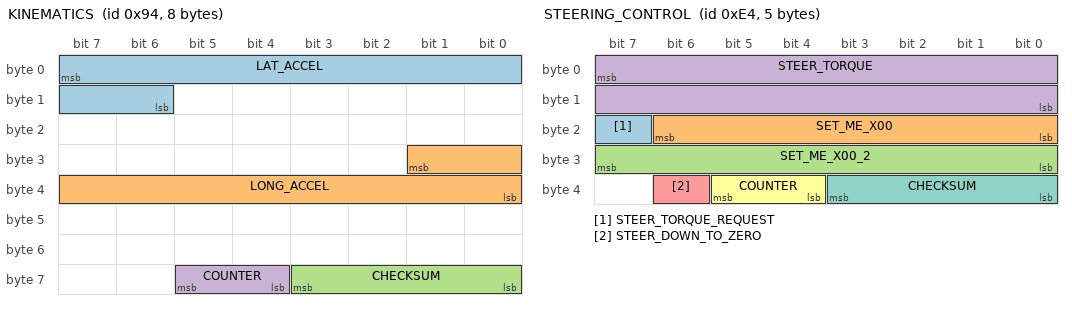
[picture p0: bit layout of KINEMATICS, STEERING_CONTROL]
BO_ 148 KINEMATICS: 8 XXX
 SG_ LAT_ACCEL : 7|10@0+ (-0.035,17.92) [-20|20] "m/s2" EON
 SG_ LONG_ACCEL : 25|10@0+ (-0.035,17.92) [-20|20] "m/s2" EON
 SG_ CHECKSUM : 59|4@0+ (1,0) [0|3] "" EON
 SG_ COUNTER : 61|2@0+ (1,0) [0|3] "" EON

BO_ 228 STEERING_CONTROL: 5 EON
 SG_ STEER_TORQUE_REQUEST : 23|1@0+ (1,0) [0|1] "" EPS
 SG_ SET_ME_X00 : 22|7@0+ (1,0) [0|127] "" EPS
 SG_ SET_ME_X00_2 : 31|8@0+ (1,0) [0|0] "" EPS
 SG_ STEER_TORQUE : 7|16@0- (1,0) [-4096|4096] "" EPS
 SG_ STEER_DOWN_TO_ZERO : 38|1@0+ (1,0) [0|1] "" EPS
 SG_ COUNTER : 37|2@0+ (1,0) [0|3] "" EPS
 SG_ CHECKSUM : 35|4@0+ (1,0) [0|15] "" EPS

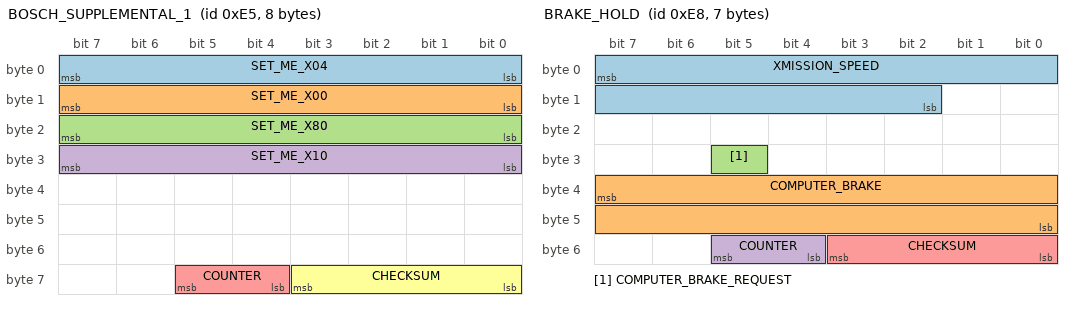
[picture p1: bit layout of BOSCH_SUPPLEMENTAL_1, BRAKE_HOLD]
BO_ 229 BOSCH_SUPPLEMENTAL_1: 8 XXX
 SG_ SET_ME_X04 : 0|8@1+ (1,0) [0|255] "" XXX
 SG_ SET_ME_X00 : 8|8@1+ (1,0) [0|255] "" XXX
 SG_ SET_ME_X80 : 16|8@1+ (1,0) [0|255] "" XXX
 SG_ SET_ME_X10 : 24|8@1+ (1,0) [0|255] "" XXX
 SG_ COUNTER : 61|2@0+ (1,0) [0|3] "" XXX
 SG_ CHECKSUM : 59|4@0+ (1,0) [0|15] "" XXX

BO_ 232 BRAKE_HOLD: 7 XXX
 SG_ XMISSION_SPEED : 7|14@0- (1,0) [1|0] "" XXX
 SG_ COMPUTER_BRAKE : 39|16@0+ (1,0) [0|0] "" XXX
 SG_ COMPUTER_BRAKE_REQUEST : 29|1@0+ (1,0) [0|0] "" XXX
 SG_ COUNTER : 53|2@0+ (1,0) [0|3] "" XXX
 SG_ CHECKSUM : 51|4@0+ (1,0) [0|15] "" XXX

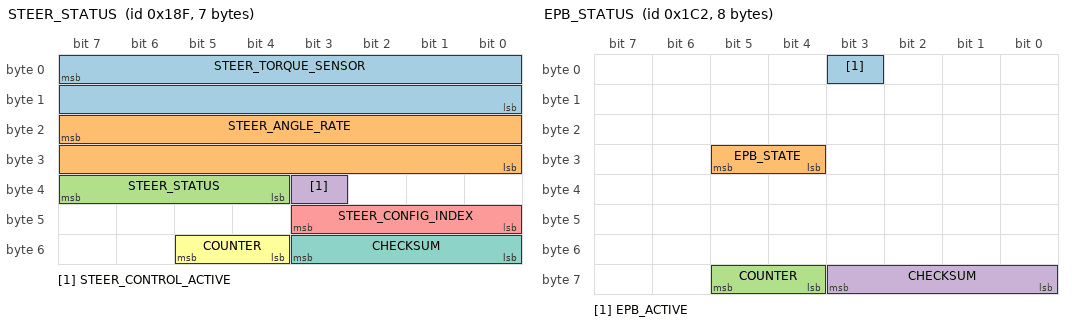
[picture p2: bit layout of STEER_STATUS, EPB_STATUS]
BO_ 399 STEER_STATUS: 7 EPS
 SG_ STEER_TORQUE_SENSOR : 7|16@0- (-1,0) [-31000|31000] "tbd" EON
 SG_ STEER_ANGLE_RATE : 23|16@0- (-0.1,0) [-31000|31000] "deg/s" EON
 SG_ STEER_STATUS : 39|4@0+ (1,0) [0|15] "" EON
 SG_ STEER_CONTROL_ACTIVE : 35|1@0+ (1,0) [0|1] "" EON
 SG_ STEER_CONFIG_INDEX : 43|4@0+ (1,0) [0|15] "" EON
 SG_ COUNTER : 53|2@0+ (1,0) [0|3] "" EON
 SG_ CHECKSUM : 51|4@0+ (1,0) [0|15] "" EON

BO_ 450 EPB_STATUS: 8 EPB
 SG_ EPB_ACTIVE : 3|1@0+ (1,0) [0|1] "" EON
 SG_ EPB_STATE : 29|2@0+ (1,0) [0|3] "" EON
 SG_ COUNTER : 61|2@0+ (1,0) [0|3] "" XXX
 SG_ CHECKSUM : 59|4@0+ (1,0) [0|15] "" XXX

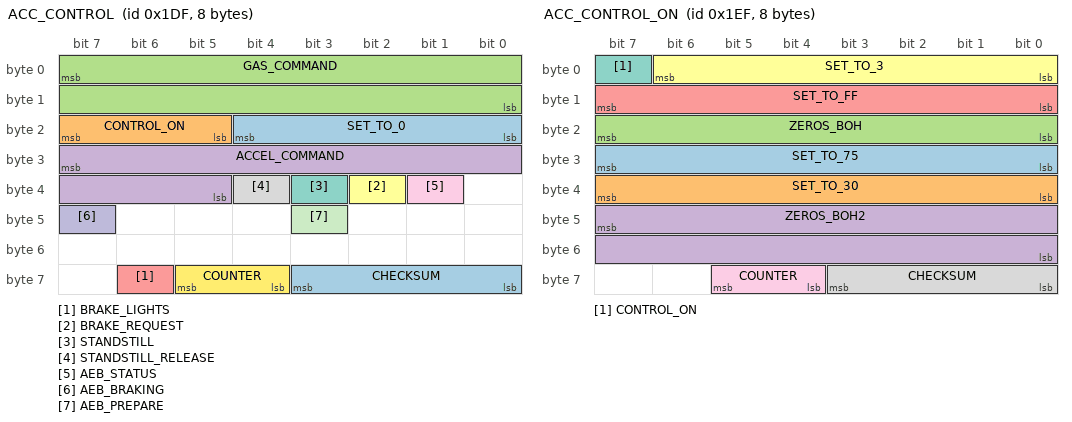
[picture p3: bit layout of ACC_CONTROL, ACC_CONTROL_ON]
BO_ 479 ACC_CONTROL: 8 EON
 SG_ SET_TO_0 : 20|5@0+ (1,0) [0|1] "" XXX
 SG_ CONTROL_ON : 23|3@0+ (1,0) [0|5] "" XXX
 SG_ GAS_COMMAND : 7|16@0- (1,0) [0|0] "" XXX
 SG_ ACCEL_COMMAND : 31|11@0- (0.01,0) [0|0] "m/s2" XXX
 SG_ BRAKE_LIGHTS : 62|1@0+ (1,0) [0|1] "" XXX
 SG_ BRAKE_REQUEST : 34|1@0+ (1,0) [0|1] "" XXX
 SG_ STANDSTILL : 35|1@0+ (1,0) [0|1] "" XXX
 SG_ STANDSTILL_RELEASE : 36|1@0+ (1,0) [0|1] "" XXX
 SG_ AEB_STATUS : 33|1@0+ (1,0) [0|1] "" XXX
 SG_ AEB_BRAKING : 47|1@0+ (1,0) [0|1] "" XXX
 SG_ AEB_PREPARE : 43|1@0+ (1,0) [0|1] "" XXX
 SG_ COUNTER : 61|2@0+ (1,0) [0|3] "" XXX
 SG_ CHECKSUM : 59|4@0+ (1,0) [0|15] "" XXX

BO_ 495 ACC_CONTROL_ON: 8 XXX
 SG_ SET_TO_75 : 31|8@0+ (1,0) [0|255] "" XXX
 SG_ SET_TO_30 : 39|8@0+ (1,0) [0|255] "" XXX
 SG_ ZEROS_BOH : 23|8@0+ (1,0) [0|255] "" XXX
 SG_ ZEROS_BOH2 : 47|16@0+ (1,0) [0|255] "" XXX
 SG_ SET_TO_FF : 15|8@0+ (1,0) [0|255] "" XXX
 SG_ SET_TO_3 : 6|7@0+ (1,0) [0|4095] "" XXX
 SG_ CONTROL_ON : 7|1@0+ (1,0) [0|1] "" XXX
 SG_ CHECKSUM : 59|4@0+ (1,0) [0|15] "" XXX
 SG_ COUNTER : 61|2@0+ (1,0) [0|3] "" XXX

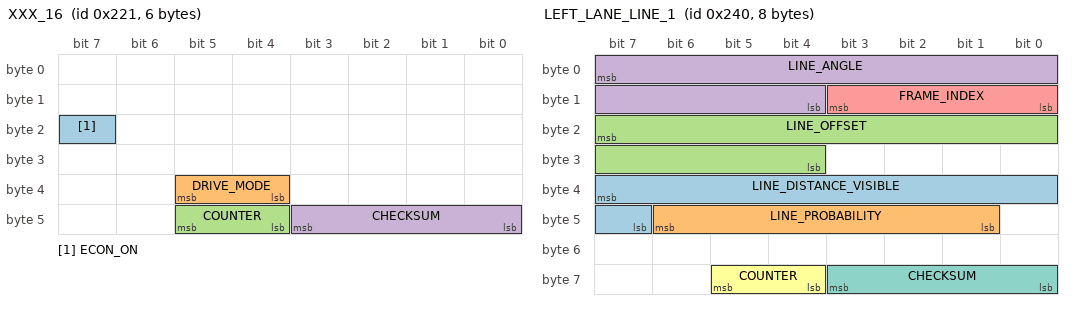
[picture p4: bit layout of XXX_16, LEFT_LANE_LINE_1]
BO_ 545 XXX_16: 6 SCM
 SG_ ECON_ON : 23|1@0+ (1,0) [0|1] "" XXX
 SG_ DRIVE_MODE : 37|2@0+ (1,0) [0|3] "" XXX
 SG_ COUNTER : 45|2@0+ (1,0) [0|3] "" BDY
 SG_ CHECKSUM : 43|4@0+ (1,0) [0|15] "" BDY

BO_ 576 LEFT_LANE_LINE_1: 8 CAM
 SG_ LINE_DISTANCE_VISIBLE : 39|9@0+ (1,0) [0|1] "" XXX
 SG_ LINE_PROBABILITY : 46|6@0+ (0.015625,0) [0|1] "" XXX
 SG_ LINE_OFFSET : 23|12@0+ (0.004,-8.192) [0|1] "Meters" XXX
 SG_ LINE_ANGLE : 7|12@0+ (0.0005,-1.024) [0|1] "" XXX
 SG_ FRAME_INDEX : 8|4@1+ (1,0) [0|15] "" XXX
 SG_ COUNTER : 61|2@0+ (1,0) [0|1] "" XXX
 SG_ CHECKSUM : 59|4@0+ (1,0) [0|1] "" XXX

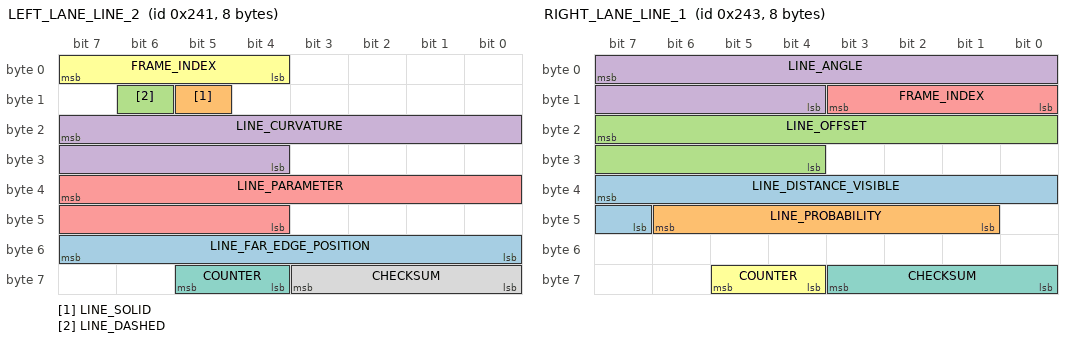
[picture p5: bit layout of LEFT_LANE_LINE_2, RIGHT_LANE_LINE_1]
BO_ 577 LEFT_LANE_LINE_2: 8 CAM
 SG_ LINE_FAR_EDGE_POSITION : 55|8@0+ (1,-128) [0|1] "" XXX
 SG_ LINE_SOLID : 13|1@0+ (1,0) [0|1] "" XXX
 SG_ LINE_DASHED : 14|1@0+ (1,0) [0|1] "" XXX
 SG_ LINE_CURVATURE : 23|12@0+ (0.00001,-0.02048) [0|1] "" XXX
 SG_ LINE_PARAMETER : 39|12@0+ (1,0) [0|1] "" XXX
 SG_ FRAME_INDEX : 7|4@0+ (1,0) [0|15] "" XXX
 SG_ COUNTER : 61|2@0+ (1,0) [0|1] "" XXX
 SG_ CHECKSUM : 59|4@0+ (1,0) [0|1] "" XXX

BO_ 579 RIGHT_LANE_LINE_1: 8 CAM
 SG_ LINE_DISTANCE_VISIBLE : 39|9@0+ (1,0) [0|1] "" XXX
 SG_ LINE_PROBABILITY : 46|6@0+ (0.015625,0) [0|1] "" XXX
 SG_ LINE_OFFSET : 23|12@0+ (0.004,-8.192) [0|1] "Meters" XXX
 SG_ LINE_ANGLE : 7|12@0+ (0.0005,-1.024) [0|1] "" XXX
 SG_ FRAME_INDEX : 8|4@1+ (1,0) [0|15] "" XXX
 SG_ COUNTER : 61|2@0+ (1,0) [0|1] "" XXX
 SG_ CHECKSUM : 59|4@0+ (1,0) [0|1] "" XXX

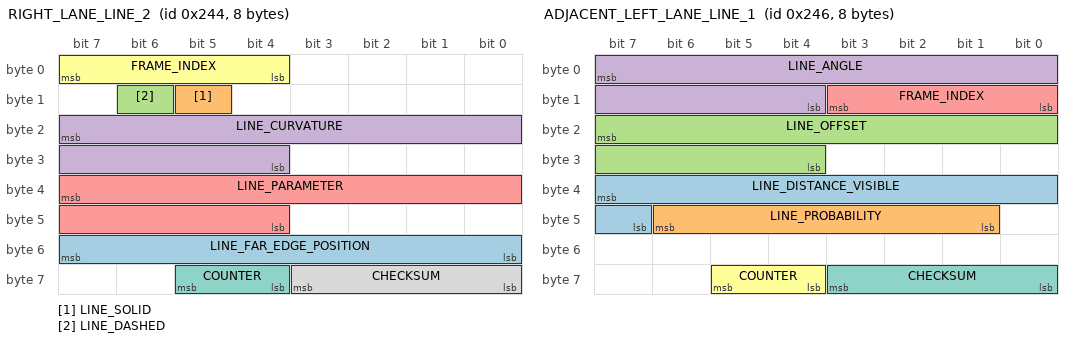
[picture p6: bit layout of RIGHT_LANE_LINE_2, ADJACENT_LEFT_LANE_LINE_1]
BO_ 580 RIGHT_LANE_LINE_2: 8 CAM
 SG_ LINE_FAR_EDGE_POSITION : 55|8@0+ (1,-128) [0|1] "" XXX
 SG_ LINE_SOLID : 13|1@0+ (1,0) [0|1] "" XXX
 SG_ LINE_DASHED : 14|1@0+ (1,0) [0|1] "" XXX
 SG_ LINE_CURVATURE : 23|12@0+ (0.00001,-0.02048) [0|1] "" XXX
 SG_ LINE_PARAMETER : 39|12@0+ (1,0) [0|1] "" XXX
 SG_ FRAME_INDEX : 7|4@0+ (1,0) [0|15] "" XXX
 SG_ COUNTER : 61|2@0+ (1,0) [0|1] "" XXX
 SG_ CHECKSUM : 59|4@0+ (1,0) [0|1] "" XXX

BO_ 582 ADJACENT_LEFT_LANE_LINE_1: 8 CAM
 SG_ LINE_DISTANCE_VISIBLE : 39|9@0+ (1,0) [0|1] "" XXX
 SG_ LINE_PROBABILITY : 46|6@0+ (0.015625,0) [0|1] "" XXX
 SG_ LINE_OFFSET : 23|12@0+ (0.004,-8.192) [0|1] "Meters" XXX
 SG_ LINE_ANGLE : 7|12@0+ (0.0005,-1.024) [0|1] "" XXX
 SG_ FRAME_INDEX : 8|4@1+ (1,0) [0|15] "" XXX
 SG_ COUNTER : 61|2@0+ (1,0) [0|1] "" XXX
 SG_ CHECKSUM : 59|4@0+ (1,0) [0|1] "" XXX

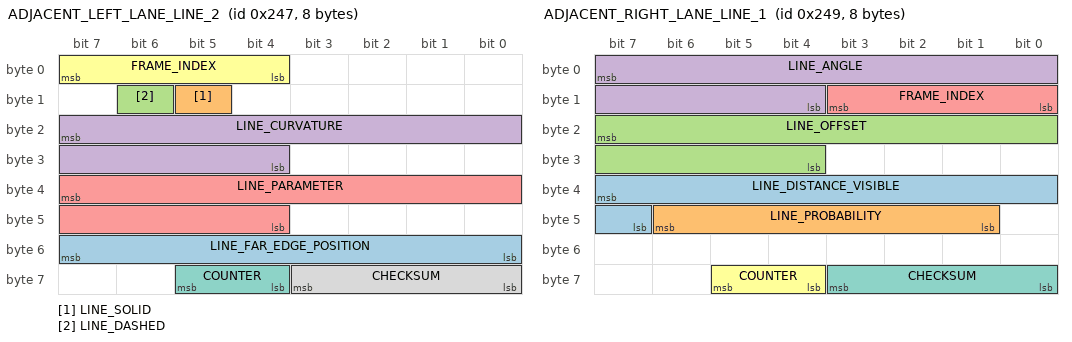
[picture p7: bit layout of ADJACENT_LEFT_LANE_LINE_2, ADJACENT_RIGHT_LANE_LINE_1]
BO_ 583 ADJACENT_LEFT_LANE_LINE_2: 8 CAM
 SG_ LINE_FAR_EDGE_POSITION : 55|8@0+ (1,-128) [0|1] "" XXX
 SG_ LINE_SOLID : 13|1@0+ (1,0) [0|1] "" XXX
 SG_ LINE_DASHED : 14|1@0+ (1,0) [0|1] "" XXX
 SG_ LINE_CURVATURE : 23|12@0+ (0.00001,-0.02048) [0|1] "" XXX
 SG_ LINE_PARAMETER : 39|12@0+ (1,0) [0|1] "" XXX
 SG_ FRAME_INDEX : 7|4@0+ (1,0) [0|15] "" XXX
 SG_ COUNTER : 61|2@0+ (1,0) [0|1] "" XXX
 SG_ CHECKSUM : 59|4@0+ (1,0) [0|1] "" XXX

BO_ 585 ADJACENT_RIGHT_LANE_LINE_1: 8 CAM
 SG_ LINE_DISTANCE_VISIBLE : 39|9@0+ (1,0) [0|1] "" XXX
 SG_ LINE_PROBABILITY : 46|6@0+ (0.015625,0) [0|1] "" XXX
 SG_ LINE_OFFSET : 23|12@0+ (0.004,-8.192) [0|1] "Meters" XXX
 SG_ LINE_ANGLE : 7|12@0+ (0.0005,-1.024) [0|1] "" XXX
 SG_ FRAME_INDEX : 8|4@1+ (1,0) [0|15] "" XXX
 SG_ COUNTER : 61|2@0+ (1,0) [0|1] "" XXX
 SG_ CHECKSUM : 59|4@0+ (1,0) [0|1] "" XXX

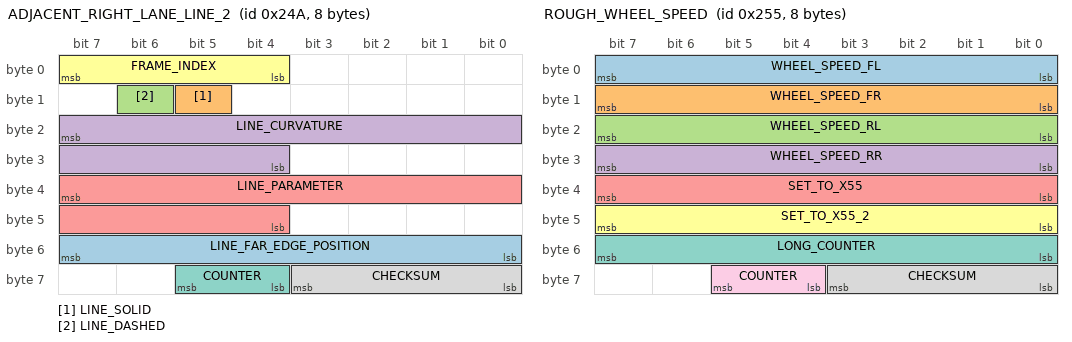
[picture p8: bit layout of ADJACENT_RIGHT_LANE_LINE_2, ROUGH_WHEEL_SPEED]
BO_ 586 ADJACENT_RIGHT_LANE_LINE_2: 8 CAM
 SG_ LINE_FAR_EDGE_POSITION : 55|8@0+ (1,-128) [0|1] "" XXX
 SG_ LINE_SOLID : 13|1@0+ (1,0) [0|1] "" XXX
 SG_ LINE_DASHED : 14|1@0+ (1,0) [0|1] "" XXX
 SG_ LINE_CURVATURE : 23|12@0+ (0.00001,-0.02048) [0|1] "" XXX
 SG_ LINE_PARAMETER : 39|12@0+ (1,0) [0|1] "" XXX
 SG_ FRAME_INDEX : 7|4@0+ (1,0) [0|15] "" XXX
 SG_ COUNTER : 61|2@0+ (1,0) [0|1] "" XXX
 SG_ CHECKSUM : 59|4@0+ (1,0) [0|1] "" XXX

BO_ 597 ROUGH_WHEEL_SPEED: 8 VSA
 SG_ WHEEL_SPEED_FL : 7|8@0+ (1,0) [0|255] "mph" EON
 SG_ WHEEL_SPEED_FR : 15|8@0+ (1,0) [0|255] "mph" EON
 SG_ WHEEL_SPEED_RL : 23|8@0+ (1,0) [0|255] "mph" EON
 SG_ WHEEL_SPEED_RR : 31|8@0+ (1,0) [0|255] "mph" EON
 SG_ SET_TO_X55 : 39|8@0+ (1,0) [0|255] "" XXX
 SG_ SET_TO_X55_2 : 47|8@0+ (1,0) [0|255] "" EON
 SG_ LONG_COUNTER : 55|8@0+ (1,0) [0|255] "" XXX
 SG_ CHECKSUM : 59|4@0+ (1,0) [0|15] "" XXX
 SG_ COUNTER : 61|2@0+ (1,0) [0|3] "" XXX

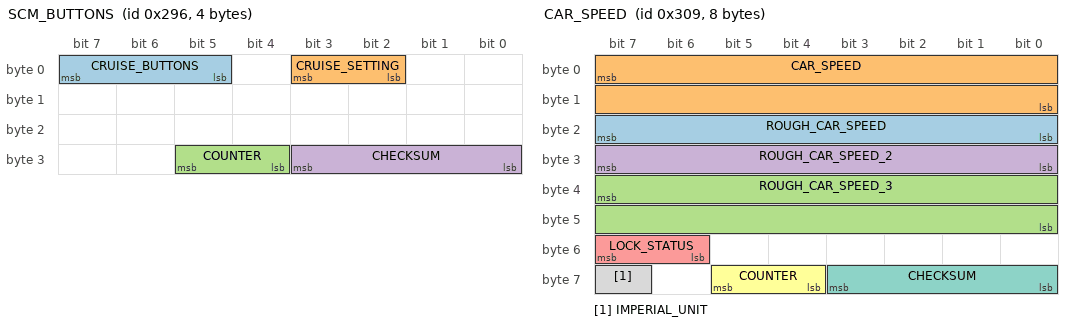
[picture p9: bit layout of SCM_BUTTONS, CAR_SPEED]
BO_ 662 SCM_BUTTONS: 4 SCM
 SG_ CRUISE_BUTTONS : 7|3@0+ (1,0) [0|7] "" EON
 SG_ CRUISE_SETTING : 3|2@0+ (1,0) [0|3] "" EON
 SG_ COUNTER : 29|2@0+ (1,0) [0|3] "" EON
 SG_ CHECKSUM : 27|4@0+ (1,0) [0|15] "" EON

BO_ 777 CAR_SPEED: 8 PCM
 SG_ ROUGH_CAR_SPEED : 23|8@0+ (1,0) [0|255] "mph" XXX
 SG_ CAR_SPEED : 7|16@0+ (0.01,0) [0|65535] "kph" XXX
 SG_ ROUGH_CAR_SPEED_3 : 39|16@0+ (0.01,0) [0|65535] "kph" XXX
 SG_ ROUGH_CAR_SPEED_2 : 31|8@0+ (1,0) [0|255] "mph" XXX
 SG_ LOCK_STATUS : 55|2@0+ (1,0) [0|255] "" XXX
 SG_ COUNTER : 61|2@0+ (1,0) [0|3] "" XXX
 SG_ CHECKSUM : 59|4@0+ (1,0) [0|15] "" XXX
 SG_ IMPERIAL_UNIT : 63|1@0+ (1,0) [0|1] "" XXX

BO_ 780 ACC_HUD: 8 ADAS
 SG_ CRUISE_SPEED : 31|8@0+ (1,0) [0|255] "kph" BDY
 SG_ DTC_MODE : 39|1@0+ (1,0) [0|1] "" BDY
 SG_ BOH : 38|1@0+ (1,0) [0|1] "" BDY
 SG_ FCM_PROBLEM : 34|1@0+ (1,0) [0|1] "" BDY
 SG_ RADAR_OBSTRUCTED : 33|1@0+ (1,0) [0|1] "" BDY
 SG_ ENABLE_MINI_CAR : 32|1@0+ (1,0) [0|1] "" BDY
 SG_ BOH_3 : 43|1@0+ (1,0) [0|3] "" BDY
 SG_ BOH_4 : 42|1@0+ (1,0) [0|3] "" BDY
 SG_ BOH_5 : 41|1@0+ (1,0) [0|3] "" BDY
 SG_ CRUISE_CONTROL_LABEL : 40|1@0+ (1,0) [0|3] "" BDY
 SG_ ZEROS_BOH : 7|24@0+ (0.002759506,0) [0|100] "m/s" BDY
 SG_ FCM_OFF : 35|1@0+ (1,0) [0|1] "" BDY
 SG_ SET_TO_1 : 36|1@0+ (1,0) [0|1] "" XXX
 SG_ HUD_DISTANCE : 47|2@0+ (1,0) [0|3] "" BDY
 SG_ HUD_LEAD : 45|2@0+ (1,0) [0|3] "" BDY
 SG_ ACC_PROBLEM : 37|1@0+ (1,0) [0|1] "" BDY
 SG_ ACC_ON : 52|1@0+ (1,0) [0|1] "" XXX
 SG_ BOH_6 : 51|4@0+ (1,0) [0|15] "" XXX
 SG_ SET_TO_X1 : 55|1@0+ (1,0) [0|1] "" XXX
 SG_ IMPERIAL_UNIT : 54|1@0+ (1,0) [0|1] "" XXX
 SG_ COUNTER : 61|2@0+ (1,0) [0|3] "" XXX
 SG_ CHECKSUM : 59|4@0+ (1,0) [0|15] "" XXX

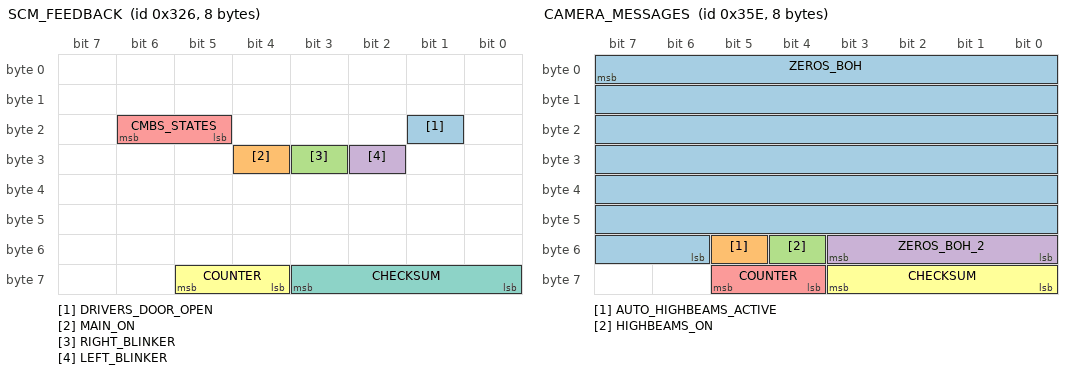
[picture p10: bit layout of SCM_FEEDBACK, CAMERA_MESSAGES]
BO_ 806 SCM_FEEDBACK: 8 SCM
 SG_ DRIVERS_DOOR_OPEN : 17|1@0+ (1,0) [0|1] "" XXX
 SG_ MAIN_ON : 28|1@0+ (1,0) [0|1] "" EON
 SG_ RIGHT_BLINKER : 27|1@0+ (1,0) [0|1] "" EON
 SG_ LEFT_BLINKER : 26|1@0+ (1,0) [0|1] "" EON
 SG_ CMBS_STATES : 22|2@0+ (1,0) [0|3] "" EON
 SG_ COUNTER : 61|2@0+ (1,0) [0|3] "" XXX
 SG_ CHECKSUM : 59|4@0+ (1,0) [0|15] "" XXX

BO_ 862 CAMERA_MESSAGES: 8 CAM
 SG_ ZEROS_BOH : 7|50@0+ (1,0) [0|127] "" BDY
 SG_ AUTO_HIGHBEAMS_ACTIVE : 53|1@0+ (1,0) [0|1] "" XXX
 SG_ HIGHBEAMS_ON : 52|1@0+ (1,0) [0|1] "" XXX
 SG_ ZEROS_BOH_2 : 51|4@0+ (1,0) [0|15] "" XXX
 SG_ COUNTER : 61|2@0+ (1,0) [0|3] "" XXX
 SG_ CHECKSUM : 59|4@0+ (1,0) [0|15] "" XXX

BO_ 13274 LKAS_HUD_A: 5 ADAS
 SG_ CAM_TEMP_HIGH : 7|1@0+ (1,0) [0|255] "" BDY
 SG_ SET_ME_X41 : 6|7@0+ (1,0) [0|127] "" BDY
 SG_ BOH : 6|7@0+ (1,0) [0|127] "" BDY
 SG_ DASHED_LANES : 14|1@0+ (1,0) [0|1] "" BDY
 SG_ DTC : 13|1@0+ (1,0) [0|1] "" BDY
 SG_ LKAS_PROBLEM : 12|1@0+ (1,0) [0|1] "" BDY
 SG_ LKAS_OFF : 11|1@0+ (1,0) [0|1] "" BDY
 SG_ SOLID_LANES : 10|1@0+ (1,0) [0|1] "" BDY
 SG_ LDW_RIGHT : 9|1@0+ (1,0) [0|1] "" BDY
 SG_ STEERING_REQUIRED : 8|1@0+ (1,0) [0|1] "" BDY
 SG_ BOH : 23|2@0+ (1,0) [0|4] "" BDY
 SG_ LDW_PROBLEM : 21|1@0+ (1,0) [0|1] "" BDY
 SG_ BEEP : 17|2@0+ (1,0) [0|1] "" BDY
 SG_ SET_ME_X01 : 20|1@0+ (1,0) [0|1] "" BDY
 SG_ LDW_ON : 28|1@0+ (1,0) [0|1] "" BDY
 SG_ LDW_OFF : 27|1@0+ (1,0) [0|1] "" BDY
 SG_ CLEAN_WINDSHIELD : 26|1@0+ (1,0) [0|1] "" BDY
 SG_ COUNTER : 37|2@0+ (1,0) [0|3] "" BDY
 SG_ CHECKSUM : 35|4@0+ (1,0) [0|15] "" BDY

BO_ 13275 LKAS_HUD_B: 8 ADAS
 SG_ CAM_TEMP_HIGH : 7|1@0+ (1,0) [0|255] "" BDY
 SG_ SET_ME_X41 : 6|7@0+ (1,0) [0|127] "" BDY
 SG_ BOH : 6|7@0+ (1,0) [0|127] "" BDY
 SG_ DASHED_LANES : 14|1@0+ (1,0) [0|1] "" BDY
 SG_ DTC : 13|1@0+ (1,0) [0|1] "" BDY
 SG_ LKAS_PROBLEM : 12|1@0+ (1,0) [0|1] "" BDY
 SG_ LKAS_OFF : 11|1@0+ (1,0) [0|1] "" BDY
 SG_ SOLID_LANES : 10|1@0+ (1,0) [0|1] "" BDY
 SG_ LDW_RIGHT : 9|1@0+ (1,0) [0|1] "" BDY
 SG_ STEERING_REQUIRED : 8|1@0+ (1,0) [0|1] "" BDY
 SG_ BOH : 23|2@0+ (1,0) [0|4] "" BDY
 SG_ LDW_PROBLEM : 21|1@0+ (1,0) [0|1] "" BDY
 SG_ BEEP : 17|2@0+ (1,0) [0|1] "" BDY
 SG_ SET_ME_X01 : 20|1@0+ (1,0) [0|1] "" BDY
 SG_ LDW_ON : 28|1@0+ (1,0) [0|1] "" BDY
 SG_ LDW_OFF : 27|1@0+ (1,0) [0|1] "" BDY
 SG_ CLEAN_WINDSHIELD : 26|1@0+ (1,0) [0|1] "" BDY
 SG_ COUNTER : 61|2@0+ (1,0) [0|3] "" BDY
 SG_ CHECKSUM : 59|4@0+ (1,0) [0|15] "" BDY

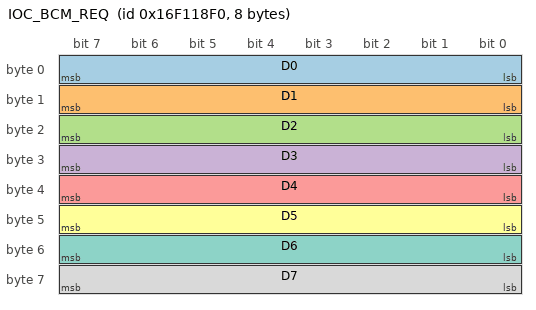
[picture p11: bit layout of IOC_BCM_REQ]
BO_ 384899312 IOC_BCM_REQ: 8 DIAG
 SG_ D0 : 7|8@0+ (1,0) [0|255] "" BCM
 SG_ D1 : 15|8@0+ (1,0) [0|255] "" BCM
 SG_ D2 : 23|8@0+ (1,0) [0|255] "" BCM
 SG_ D3 : 31|8@0+ (1,0) [0|255] "" BCM
 SG_ D4 : 39|8@0+ (1,0) [0|255] "" BCM
 SG_ D5 : 47|8@0+ (1,0) [0|255] "" BCM
 SG_ D6 : 55|8@0+ (1,0) [0|255] "" BCM
 SG_ D7 : 63|8@0+ (1,0) [0|255] "" BCM

BO_ 384954392 IOC_BCM_FDBK: 8 BCM
 SG_ D0 : 7|8@0+ (1,0) [0|255] "" DIAG,OP
 SG_ D1 : 14|8@0+ (1,0) [0|255] "" DIAG,OP

CM_ SG_ 450 EPB_STATE "3: On, 2: Disengaging, 1: Engaging, 0: Off";
CM_ SG_ 479 CONTROL_ON "Set to 5 when car is being controlled";
CM_ SG_ 479 AEB_STATUS "set for the duration of AEB event";
CM_ SG_ 479 AEB_BRAKING "set when braking is commanded during AEB event";
CM_ SG_ 479 AEB_PREPARE "set 1s before AEB";
CM_ SG_ 576 LINE_DISTANCE_VISIBLE "Length of line visible, undecoded";
CM_ SG_ 577 LINE_FAR_EDGE_POSITION "Appears to be a measure of line thickness, indicates location of the portion of the line furthest from the car, undecoded";
CM_ SG_ 577 LINE_PARAMETER "Unclear if this is low quality line curvature rate or if this is something else, but it is correlated with line curvature, undecoded";
CM_ SG_ 577 LINE_DASHED "1 = line is dashed";
CM_ SG_ 577 LINE_SOLID "1 = line is solid";

VAL_ 399 STEER_STATUS 6 "tmp_fault" 5 "fault_1" 4 "no_torque_alert_2" 3 "low_speed_lockout" 2 "no_torque_alert_1" 0 "normal";
